# RZT2ME register map
Vendor: Renesas Electronics Corporation; Series: RZT; File version: 1.00.00
CPU: other r0p0, little endian, MPU, no FPU, VTOR, 4 interrupt priority bits, 624 interrupts
Registers are 32-bit, read-write, reset 0x0 unless marked. A register's access mark holds for its fields unless they carry their own. Offsets are from the block's base; [hi:lo] are bit positions; {n}, {i} and the like mark numbered series; <NAME> marks a mode.

## SPI0 — Serial Peripheral Interface 0
Base 0x80003000
Same registers: SPI1 0x80003400, SPI2 0x80003800, SPI3 0x81002000
0x00 SPDR — SPI Data Register
  [31:0] SPD — The SPI data register (SPDR) is used to store SPI's transmit data and receive data. Transmit buffers and receive buffers independently function.
0x00 SPDR_HA 16-bit (alternate view of SPDR) — SPI Data Register
0x00 SPDR_BY 8-bit (alternate view of SPDR) — SPI Data Register
0x04 SPCKD 8-bit — SPI Clock Delay Register
  [2:0] SCKDL — RSPCK Delay Setting
    {v}={v+1} RSPCK (v=0..7)
0x05 SSLND 8-bit — SPI Slave Select Negation Delay Register
  [2:0] SLNDL — SSL Negation Delay Bits
    {v}={v+1} RSPCK [Master mode] {v+1} PCLKSPIn + (2~3 PCLKSPIn (Synchronization delay)) [TI-SSP case in Slave Mode] (v=0..7)
0x06 SPND 8-bit — SPI Next-Access Delay Register
  [2:0] SPNDL — SPI Next-Access Delay Bits
    {v}={v+1} RSPCK + 5 PCLKSPIn (v=0..4); 5=6 RSPCK+ 5 PCLKSPIn; 6=7 RSPCK + 5 PCLKSPIn; 7=8 RSPCK + 5 PCLKSPIn
0x07 MRCKD 8-bit — SPI ClocK Digital control Register for Master Receive
  [2:0] ARST — Receive Sampling Timing Adjustment Bits
    {v}={v} PCLKSPIn delay (v=0..7)
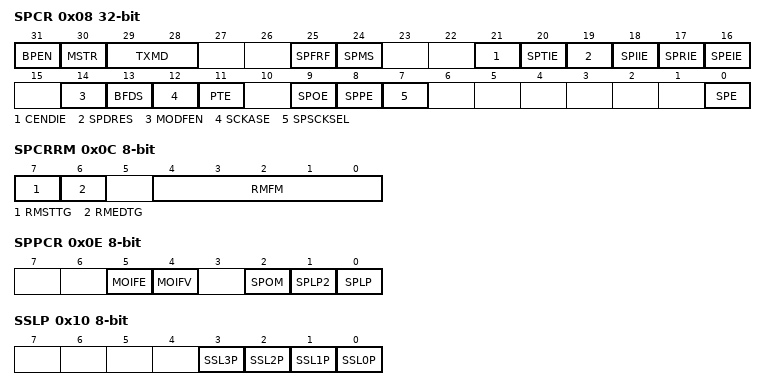
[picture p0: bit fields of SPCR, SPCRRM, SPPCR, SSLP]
0x08 SPCR — SPI Control Register
  [31] BPEN — Synchronization Circuit Bypass Enable
    0=Non-Bypass; 1=Bypass
  [30] MSTR — SPI Master/Slave Mode Select
    0=Slave mode; 1=Master mode
  [29:28] TXMD — Communication Mode Select
    0=Transmit-Receive; 1=Transmit only; 0b1x=Receive only
  [25] SPFRF — SPI Frame Format Select
    0=Motorola-SPI; 1=TI-SSP
  [24] SPMS — SPI Function Enable
    0=SPI operation (4-wire); 1=Clock synchronous operation (3-wire)
  [21] CENDIE — SPI Communication End Interrupt Enable
    0=Communication end interrupt request is disabled; 1=Communication end interrupt request is enabled
  [20] SPTIE — SPI Transmit Buffer Empty Interrupt Enable
    0=SPI transmit buffer empty interrupt request is disabled; 1=SPI transmit buffer empty interrupt request is enabled
  [19] SPDRES — SPI Receive Data Ready Error Select
    0=Receive data full interrupt; 1=Error interrupt
  [18] SPIIE — SPI Idle Interrupt Enable
    0=Idle interrupt request is disabled; 1=Idle interrupt request is enabled
  [17] SPRIE — SPI Receive Buffer Full Interrupt Enable
    0=SPI receive buffer full interrupt request is disabled; 1=SPI receive buffer full interrupt request is enabled
  [16] SPEIE — SPI Error Interrupt Enable
    0=SPI error interrupt request is disabled; 1=SPI error interrupt request is enabled
  [14] MODFEN — Mode Fault Error Detection Enable
    0=Mode fault error detection is disabled; 1=Mode fault error detection is enabled
  [13] BFDS — Between Burst Transfer Frames Delay Select
    0=Delay (RSPCK delay, SSL negation delay and next-access delay) between frames is inserted in burst transfer; 1=Delay between frames is not inserted in burst transfer
  [12] SCKASE — RSPCK Auto-Stop Function Enable
    0=RSPCK auto-stop function is disabled; 1=RSPCK auto-stop function is enabled
  [11] PTE — Parity Self-Diagnosis Enable
    0=Parity circuit self-diagnosis function is disabled; 1=Parity circuit self-diagnosis function is enabled
  [9] SPOE — Parity Mode
    0=Even parity is used for transmission and reception; 1=Odd parity is used for transmission and reception
  [8] SPPE — Parity Enable
    0=A parity bit is not added to transmit data. Received-data parity check is not performed.; 1=A parity bit is added to transmit data. Received-data parity check is performed.
  [7] SPSCKSEL — SPI Master Receive Clock Select
    0=MRIOCLK (Adjust with Analog Delay (SPCR2.SPSCKDL)); 1=MRCLK (Adjust with Digital Delay (MRCKD.ARST))
  [0] SPE — SPI Function Enable
    0=SPI function is disabled; 1=SPI function is enabled
0x0C SPCRRM 8-bit — SPI Control Register for Master Receive only
  [7] RMSTTG wo — Reading value is always 0.
  [6] RMEDTG wo — Reading value is always 0.
  [4:0] RMFM — Frame processing count setting in Master Receive only
0x0D SPDRCR 8-bit — SPI Control Register for Received Data Ready Detection
  [7:0] SPDRC
0x0E SPPCR 8-bit — SPI Pin Control Register
  [5] MOIFE — MOSI Idle Value Fixing Enable
    0=The MOSI output value is the last data of previous transfer; 1=The MOSI output value is the set MOIFV bit value
  [4] MOIFV — MOSI Idle Fixed Value
    0=The fixed value of MOSI idle = 0; 1=The fixed value of MOSI idle = 1
  [2] SPOM — SPI Output Pin Mode
    0=CMOS output; 1=Open-drain output
  [1] SPLP2 — SPI Loopback 2
    0=Normal mode; 1=Loopback mode (data is not inverted for transmission)
  [0] SPLP — SPI Loopback
    0=Normal mode; 1=Loopback mode (data is inverted for transmission)
0x0F SPCR2 8-bit — SPI Control Register 2
  [2:0] SPSCKDL — SPI Master Receive Clock Analog Delay
    0=No delay; 1=1.1 ns (max); 2=2.2 ns (max); 3=3.3 ns (max); 4=4.4 ns (max); 5=5.5 ns (max); 6=6.6 ns (max); 7=7.7 ns (max)
0x10 SSLP 8-bit — SPI Slave Select Polarity Register
  [n] SSL{n}P (n=0..3) — SSL{n} Signal Polarity Setting
    0=In the Motorola-SPI case, the SSL{n} signal is active low (0). In the TI-SSP case, the SSL{n} signal is active high (1).; 1=In the Motorola-SPI case, the SSL{n} signal is active high (1). In the TI-SSP case, the SSL{n} signal is active low (0).
0x11 SPBR 8-bit reset 0xFF — SPI Bit Rate Register
  [7:0] SPR — The SPBR register is used to set the bit rate in master mode. If SPBR is modified while SPCR.MSTR = 1 and SPCR.SPE = 1, subsequent operation is not guaranteed.
0x13 SPSCR 8-bit — SPI Sequence Control Register
  [2:0] SPSLN — SPI Sequence Length Specification
    0=Sequence Length = 1 (0->0->...); 1=Sequence Length = 2 (0->1->0->...); 2=Sequence Length = 3 (0->1->2->0->...); 3=Sequence Length = 4 (0->1->2->3->0->...); 4=Sequence Length = 5 (0->1->2->3->4->0->...); 5=Sequence Length = 6 (0->1->2->3->4->5->0->...); 6=Sequence Length = 7 (0->1->2->3->4->5->6->0->...); 7=Sequence Length = 8 (0->1->2->3->4->5->6->7->0->...)
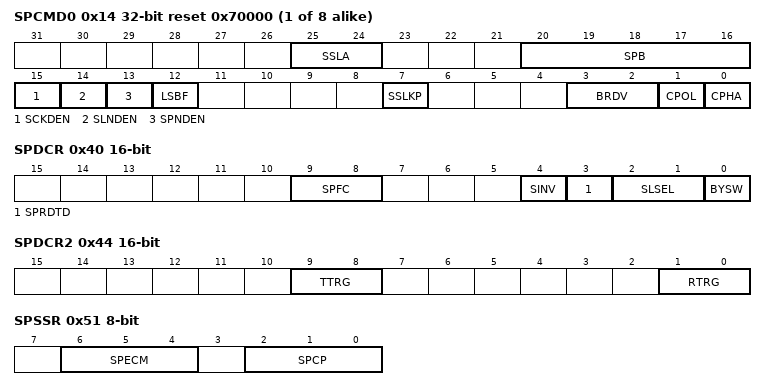
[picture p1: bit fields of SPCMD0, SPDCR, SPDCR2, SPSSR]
{0x14+4i} SPCMD{i} (i=0..7) reset 0x70000 — SPI Command Register {i} (m = 0 to 7)
  [25:24] SSLA — SSL Signal Assertion
    {v}=SSL{v} (v=0..3)
  [20:16] SPB — SPI Data Length
  [15] SCKDEN — RSPCK Delay Setting Enable
    0=RSPCK delay is 1 RSPCK. [In the Motorola-SPI case] RSPCK delay is 0 RSPCK. [In the TI-SSP case]; 1=RSPCK delay is the set value of the RSPCK delay register (SPCKD)
  [14] SLNDEN — SSL Negation Delay Setting Enable
    0=[Master] SSL negation delay is 1 RSPCK. [Slave in the TI-SSP] SSL negation delay is 1 PCLKSPIn + 2~3 PCLKSPIn (Synchronization delay); 1=SSL negation delay is the set value of the slave select negation delay register (SSLND)
  [13] SPNDEN — SPI Next-Access Delay Enable
    0=Next-access delay is 1 RSPCK + 5 PCLKSPIn; 1=Next-access delay is the set value of the SPI next-access delay register (SPND)
  [12] LSBF — SPI LSB First
    0=MSB first; 1=LSB first
  [7] SSLKP — SSL Signal Level Hold
    0=All SSL signals are negated at the end of transfer; 1=SSL signal level is held after the transfer ends until the next access starts
  [3:2] BRDV — Bit Rate Division
    0=The base bit rate is selected; 1=Two-divided base bit rate is selected; 2=Four-divided base bit rate is selected; 3=Eight-divided base bit rate is selected
  [1] CPOL — RSPCK Polarity
    0=RSPCK in idle state is 0; 1=RSPCK in idle state is 1
  [0] CPHA — RSPCK Phase
    0=Data is sampled at an odd edge and changes at an even edge; 1=Data changes at an odd edge and is sampled at an even edge
0x40 SPDCR 16-bit — SPI Data Control Register
  [9:8] SPFC — Frame Count
    0=1 frame; 1=2 frames; 2=3 frames; 3=4 frames
  [4] SINV — Serial data invert
    0=Not invert serial data; 1=Invert serial data
  [3] SPRDTD — SPI Receive Data or Transmit Data Selection
    0=The SPDR reads the receive buffer; 1=The SPDR reads the transmit buffer
  [2:1] SLSEL — SSL Pin Output Select
  [0] BYSW — Byte Swap Operating Mode Select
    0=Byte swap is disabled; 1=Byte swap is enabled
0x44 SPDCR2 16-bit — SPI Data Control Register 2
  [9:8] TTRG — Transmission FIFO threshold setting
    {v}=Threshold {v} (v=0..3)
  [1:0] RTRG — Receive FIFO threshold setting
    {v}=Threshold {v} (v=0..3)
0x51 SPSSR 8-bit ro — SPI Sequence Status Register
  [6:4] SPECM — SPI Error Command
    {v}=SPCMD{v} (v=0..7)
  [2:0] SPCP — SPI Command Pointer
    {v}=SPCMD{v} (v=0..7)
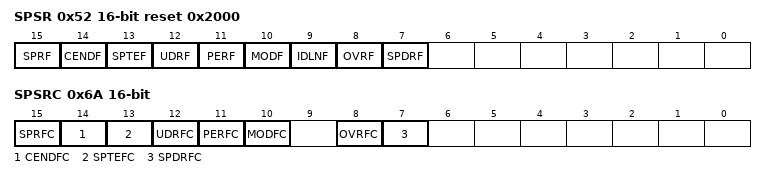
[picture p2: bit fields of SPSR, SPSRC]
0x52 SPSR 16-bit ro reset 0x2000 — SPI Status Register
  [15] SPRF — SPI Receive Buffer Full Flag
    0=The number of data stored in the receive FIFO <= number of frames set by the SPDCR2.RTRG bit; 1=The number of data stored in the receive FIFO > number of frames set by the SPDCR2.RTRG bit
  [14] CENDF — Communication End Flag
    0=The SPI is not communicating or communicating; 1=The SPI communication completed
  [13] SPTEF — SPI Transmit Buffer Empty Flag
    0=The number of empty stages in the transmit FIFO <= the value set in SPDCR2.TTRG; 1=The number of empty stages in the transmit FIFO > the value set in SPDCR2.TTRG
  [12] UDRF — Underrun Error Flag
    0=Mode fault error occurred (MODF = 1); 1=Underrun error occurred (MODF = 1)
  [11] PERF — Parity Error Flag
    0=No parity error is present; 1=A parity error is present
  [10] MODF — Mode Fault Error Flag
    0=Neither mode fault error nor underrun error is present; 1=A mode fault error or underrun error is present
  [9] IDLNF — SPI Idle Flag
    0=The SPI is in the idle state; 1=The SPI is in the transfer state
  [8] OVRF — Overrun Error Flag
    0=No overrun error is present; 1=An overrun error is present
  [7] SPDRF — SPI Receive Data Ready Flag
    0=Receive data ready not detected; 1=Receive data ready detected
0x58 SPTFSR 8-bit ro reset 0x4 — SPI Transfer FIFO Status Register
  [2:0] TFDN — Transmit FIFO data empty stage number
    {v}=Number of empty stages {v} (v=0..4)
0x5C SPRFSR 8-bit ro — SPI Receive FIFO Status Register
  [2:0] RFDN — Receive FIFO data store stage number
    {v}=Number of store stages {v} (v=0..4)
0x60 SPPSR ro — SPI Poling Register
  [0] SPEPS — SPI Polling Status
    0=SPCR.SPE is 0; 1=SPCR SPE is 1
0x6A SPSRC 16-bit — SPI Status Clear Register
  [15] SPRFC wo — SPI Receive Buffer Full Flag Clear
  [14] CENDFC wo — Communication End Flag Clear
  [13] SPTEFC wo — SPI Transmit Buffer Empty Flag Clear
  [12] UDRFC wo — Underrun Error Flag Clear
  [11] PERFC wo — Parity Error Flag Clear
  [10] MODFC wo — Mode Fault Error Flag Clear
  [8] OVRFC wo — Overrun Error Flag Clear
  [7] SPDRFC wo — SPI Receive Data Ready Flag Clear
0x6C SPFCR 8-bit wo — SPI FIFO Clear Register
  [0] SPFRST — SPI FIFO clear
